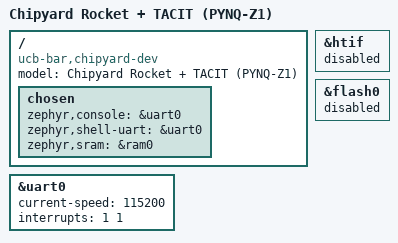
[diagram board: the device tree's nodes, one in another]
/dts-v1/;

/*
 * Rocket + TACIT on a PYNQ-Z1, as generated by Chipyard's PynqZ2RocketTacitConfig.
 *
 * The address map below is not guesswork: it is transcribed from the DTS Chipyard emits
 * alongside the Verilog, at
 *   generated-src/chipyard.harness.TestHarness.PynqZ2RocketTacitConfig/*.dts
 * Anything that disagrees with that file is a bug here, not there.
 *
 * Console: Rocket's SiFive UART is cross-connected in the PL to PS UART1 on EMIO, so its
 * output appears on the Linux side as /dev/ttyPS1 at 115200. See fpga/pynq-z2/docs/UART.md.
 */

#include <chipyard/chipyard-riscv64.dtsi>

/ {
	model = "Chipyard Rocket + TACIT (PYNQ-Z1)";
	compatible = "ucb-bar,chipyard-dev";

	chosen {
		zephyr,console = &uart0;
		zephyr,shell-uart = &uart0;
		zephyr,sram = &ram0;
	};
};

&uart0 {
	status = "okay";
	current-speed = <115200>;
	/*
	 * PLIC source 1, NOT the 3 the shared chipyard dtsi assumes. The generated DTS says
	 * `interrupts = <1>` with `riscv,ndev = <1>` -- this SoC has exactly one PLIC device
	 * and the UART is it.
	 */
	interrupts = <1 1>;
};

/* HTIF is a simulator transport: it needs a host polling tohost/fromhost. On the FPGA the
 * console is a real UART, so leave it off. */
&htif {
	status = "disabled";
};

&flash0 {
	status = "disabled";
};
